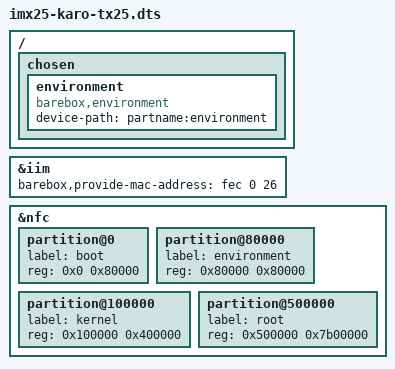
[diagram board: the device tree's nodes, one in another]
/*
 * Copyright 2012 Sascha Hauer, Pengutronix
 *
 * The code contained herein is licensed under the GNU General Public
 * License. You may obtain a copy of the GNU General Public License
 * Version 2 or later at the following locations:
 *
 * http://www.opensource.org/licenses/gpl-license.html
 * http://www.gnu.org/copyleft/gpl.html
 */

#include <arm/imx25-karo-tx25.dts>
#include "imx25.dtsi"

/ {
	chosen {
		environment {
			compatible = "barebox,environment";
			device-path = &nfc, "partname:environment";
		};
	};
};

&iim {
	barebox,provide-mac-address = <&fec 0 26>;
};

&nfc {
	#address-cells = <1>;
	#size-cells = <1>;

	partition@0 {
		label = "boot";
		reg = <0x0 0x80000>;
	};

	partition@80000 {
		label = "environment";
		reg = <0x80000 0x80000>;
	};

	partition@100000 {
		label = "kernel";
		reg = <0x100000 0x400000>;
	};

	partition@500000 {
		label = "root";
		reg = <0x500000 0x7b00000>;
	};
};
